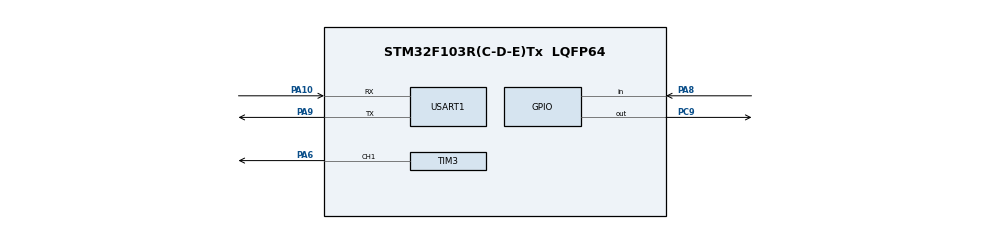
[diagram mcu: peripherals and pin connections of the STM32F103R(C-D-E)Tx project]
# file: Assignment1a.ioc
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Dma.Request0=USART1_RX
Dma.Request1=USART1_TX
Dma.USART1_RX.0.Direction=DMA_PERIPH_TO_MEMORY
Dma.USART1_RX.0.Instance=DMA1_Channel5
Dma.USART1_RX.0.MemDataAlignment=DMA_MDATAALIGN_BYTE
Dma.USART1_RX.0.MemInc=DMA_MINC_ENABLE
Dma.USART1_RX.0.Mode=DMA_NORMAL
Dma.USART1_RX.0.PeriphDataAlignment=DMA_PDATAALIGN_BYTE
Dma.USART1_RX.0.PeriphInc=DMA_PINC_DISABLE
Dma.USART1_RX.0.Priority=DMA_PRIORITY_LOW
Dma.USART1_TX.1.Direction=DMA_MEMORY_TO_PERIPH
Dma.USART1_TX.1.Instance=DMA1_Channel4
Dma.USART1_TX.1.MemDataAlignment=DMA_MDATAALIGN_BYTE
Dma.USART1_TX.1.MemInc=DMA_MINC_ENABLE
Dma.USART1_TX.1.Mode=DMA_NORMAL
Dma.USART1_TX.1.PeriphDataAlignment=DMA_PDATAALIGN_BYTE
Dma.USART1_TX.1.PeriphInc=DMA_PINC_DISABLE
Dma.USART1_TX.1.Priority=DMA_PRIORITY_LOW
Mcu.Family=STM32F1
Mcu.Name=STM32F103R(C-D-E)Tx
Mcu.Package=LQFP64
NVIC.DMA1_Channel4_IRQn=true\:0\:0\:false\:false\:true\:false\:true\:true
NVIC.DMA1_Channel5_IRQn=true\:0\:0\:false\:false\:true\:false\:true\:true
NVIC.PriorityGroup=NVIC_PRIORITYGROUP_4
PA10.Mode=Asynchronous
PA10.Signal=USART1_RX
PA13.Mode=Serial_Wire
PA13.Signal=SYS_JTMS-SWDIO
PA14.Mode=Serial_Wire
PA14.Signal=SYS_JTCK-SWCLK
PA6.Signal=S_TIM3_CH1
PA8.Signal=GPIO_Input
PA9.Mode=Asynchronous
PA9.Signal=USART1_TX
PC9.Signal=GPIO_Output
ProjectManager.HeapSize=0x200
ProjectManager.StackSize=0x400
ProjectManager.TargetToolchain=STM32CubeIDE
RCC.APB1Freq_Value=8000000
RCC.APB2Freq_Value=8000000
SH.S_TIM3_CH1.0=TIM3_CH1,PWM Generation1 CH1
TIM3.Channel-PWM\ Generation1\ CH1=TIM_CHANNEL_1
USART1.VirtualMode=VM_ASYNC
VP_TIM1_VS_ClockSourceINT.Mode=Internal
VP_TIM3_VS_ClockSourceINT.Mode=Internal
board=custom

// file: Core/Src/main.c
/* USER CODE BEGIN Header */
/**
  ******************************************************************************
  * @file           : main.c
  * @brief          : Main program body
  ******************************************************************************
  * @attention
  *
  * Copyright (c) 2024 STMicroelectronics.
  * All rights reserved.
  *
  * This software is licensed under terms that can be found in the LICENSE file
  * in the root directory of this software component.
  * If no LICENSE file comes with this software, it is provided AS-IS.
  *
  ******************************************************************************
  */
/* USER CODE END Header */
#include "main.h"

/* USER CODE BEGIN Includes */
#include <stdio.h>
#include <stdlib.h>
#include <string.h>
/* USER CODE END Includes */

TIM_HandleTypeDef htim1;
TIM_HandleTypeDef htim3;

UART_HandleTypeDef huart1;
DMA_HandleTypeDef hdma_usart1_rx;
DMA_HandleTypeDef hdma_usart1_tx;

/* USER CODE BEGIN PV */
#define TRIG_PIN GPIO_PIN_9
#define TRIG_PORT GPIOC
#define ECHO_PIN GPIO_PIN_8
#define ECHO_PORT GPIOA

uint32_t pMillis;
uint32_t Value1 = 0;
uint32_t Value2 = 0;
uint16_t Distance = 0; //cm
/* USER CODE END PV */

void SystemClock_Config(void);
static void MX_GPIO_Init(void);
static void MX_DMA_Init(void);
static void MX_TIM1_Init(void);
static void MX_USART1_UART_Init(void);
static void MX_TIM3_Init(void);

int main(void)
{
	/*User code begin 1*/
	int CH1_DC = 0;
	uint8_t count = 0;
	char MSG[35] = {'\0'};
	/*User code end 1*/

	/*Reset of all peripherals, INitializes the Flash interface and the Systick*/
	HAL_Init();

	/*Configures the sys clock*/
	SystemClock_Config();

	//Initialize all configured peripherals
	MX_GPIO_Init();
	MX_TIM3_Init();
	MX_USART1_UART_Init();
	MX_TIM1_Init();
	MX_DMA_Init();

	//USER CODE BEGIN 2
	HAL_TIM_Base_Start(&htim1);
	HAL_GPIO_WritePin(TRIG_PORT, TRIG_PIN, GPIO_PIN_RESET); //pull TRIG pin LOW
	//USER CODE END 2

	//USER CODE BEGIN WHILE, INFINITE WHILE LOOP
	while (1)
	{
		HAL_GPIO_WritePin(TRIG_PORT, TRIG_PIN, GPIO_PIN_SET); //pull TRIG pin HIGH
		__HAL_TIM_SET_COUNTER(&htim1, 0);
		while(__HAL_TIM_GET_COUNTER(&htim1) < 10); //wait 10us
		HAL_GPIO_WritePin(TRIG_PORT, TRIG_PIN, GPIO_PIN_RESET); //pull TRIG pin LOW

		pMillis = HAL_GetTick(); //used for timeout, avoid infinite loop
		//wait for echo pin to go HIGH
		while(!(HAL_GPIO_ReadPin(ECHO_PORT, ECHO_PIN)) && pMillis + 10 > HAL_GetTick());
		Value1 = __HAL_TIM_GET_COUNTER(&htim1);

		pMillis = HAL_GetTick(); //used for timeout, avoid infinite loop
		//wait for echo pin to go LOW
		while((HAL_GPIO_ReadPin(ECHO_PORT, ECHO_PIN)) && pMillis + 50 > HAL_GetTick());
		Value2 = __HAL_TIM_GET_COUNTER(&htim1);

		Distance = (Value2-Value1)*0.034/2;
		sprintf(MSG, "Distance = %d\r\n", Distance);
		HAL_UART_Transmit(&huart1, MSG, sizeof(MSG), 100);
		HAL_Delay(500);

	}
	//USER CODE END WHILE
}

void SystemClock_Config(void)
{
  RCC_OscInitTypeDef RCC_OscInitStruct = {0};
  RCC_ClkInitTypeDef RCC_ClkInitStruct = {0};

  /** Initializes the RCC Oscillators according to the specified parameters
  * in the RCC_OscInitTypeDef structure.
  */
  RCC_OscInitStruct.OscillatorType = RCC_OSCILLATORTYPE_HSI;
  RCC_OscInitStruct.HSIState = RCC_HSI_ON;
  RCC_OscInitStruct.HSICalibrationValue = RCC_HSICALIBRATION_DEFAULT;
  RCC_OscInitStruct.PLL.PLLState = RCC_PLL_NONE;
  if (HAL_RCC_OscConfig(&RCC_OscInitStruct) != HAL_OK)
  {
    Error_Handler();
  }

  /** Initializes the CPU, AHB and APB buses clocks
  */
  RCC_ClkInitStruct.ClockType = RCC_CLOCKTYPE_HCLK|RCC_CLOCKTYPE_SYSCLK
                              |RCC_CLOCKTYPE_PCLK1|RCC_CLOCKTYPE_PCLK2;
  RCC_ClkInitStruct.SYSCLKSource = RCC_SYSCLKSOURCE_HSI;
  RCC_ClkInitStruct.AHBCLKDivider = RCC_SYSCLK_DIV1;
  RCC_ClkInitStruct.APB1CLKDivider = RCC_HCLK_DIV1;
  RCC_ClkInitStruct.APB2CLKDivider = RCC_HCLK_DIV1;

  if (HAL_RCC_ClockConfig(&RCC_ClkInitStruct, FLASH_LATENCY_0) != HAL_OK)
  {
    Error_Handler();
  }
}

static void MX_TIM1_Init(void)
{

  TIM_ClockConfigTypeDef sClockSourceConfig = {0};
  TIM_MasterConfigTypeDef sMasterConfig = {0};

  htim1.Instance = TIM1;
  htim1.Init.Prescaler = 0;
  htim1.Init.CounterMode = TIM_COUNTERMODE_UP;
  htim1.Init.Period = 65535;
  htim1.Init.ClockDivision = TIM_CLOCKDIVISION_DIV1;
  htim1.Init.RepetitionCounter = 0;
  htim1.Init.AutoReloadPreload = TIM_AUTORELOAD_PRELOAD_DISABLE;
  if (HAL_TIM_Base_Init(&htim1) != HAL_OK)
  {
    Error_Handler();
  }
  sClockSourceConfig.ClockSource = TIM_CLOCKSOURCE_INTERNAL;
  if (HAL_TIM_ConfigClockSource(&htim1, &sClockSourceConfig) != HAL_OK)
  {
    Error_Handler();
  }
  sMasterConfig.MasterOutputTrigger = TIM_TRGO_RESET;
  sMasterConfig.MasterSlaveMode = TIM_MASTERSLAVEMODE_DISABLE;
  if (HAL_TIMEx_MasterConfigSynchronization(&htim1, &sMasterConfig) != HAL_OK)
  {
    Error_Handler();
  }

}

static void MX_TIM3_Init(void)
{

  TIM_ClockConfigTypeDef sClockSourceConfig = {0};
  TIM_MasterConfigTypeDef sMasterConfig = {0};
  TIM_OC_InitTypeDef sConfigOC = {0};

  htim3.Instance = TIM3;
  htim3.Init.Prescaler = 0;
  htim3.Init.CounterMode = TIM_COUNTERMODE_UP;
  htim3.Init.Period = 65535;
  htim3.Init.ClockDivision = TIM_CLOCKDIVISION_DIV1;
  htim3.Init.AutoReloadPreload = TIM_AUTORELOAD_PRELOAD_DISABLE;
  if (HAL_TIM_Base_Init(&htim3) != HAL_OK)
  {
    Error_Handler();
  }
  sClockSourceConfig.ClockSource = TIM_CLOCKSOURCE_INTERNAL;
  if (HAL_TIM_ConfigClockSource(&htim3, &sClockSourceConfig) != HAL_OK)
  {
    Error_Handler();
  }
  if (HAL_TIM_PWM_Init(&htim3) != HAL_OK)
  {
    Error_Handler();
  }
  sMasterConfig.MasterOutputTrigger = TIM_TRGO_RESET;
  sMasterConfig.MasterSlaveMode = TIM_MASTERSLAVEMODE_DISABLE;
  if (HAL_TIMEx_MasterConfigSynchronization(&htim3, &sMasterConfig) != HAL_OK)
  {
    Error_Handler();
  }
  sConfigOC.OCMode = TIM_OCMODE_PWM1;
  sConfigOC.Pulse = 0;
  sConfigOC.OCPolarity = TIM_OCPOLARITY_HIGH;
  sConfigOC.OCFastMode = TIM_OCFAST_DISABLE;
  if (HAL_TIM_PWM_ConfigChannel(&htim3, &sConfigOC, TIM_CHANNEL_1) != HAL_OK)
  {
    Error_Handler();
  }
  HAL_TIM_MspPostInit(&htim3);

}

static void MX_USART1_UART_Init(void)
{

  huart1.Instance = USART1;
  huart1.Init.BaudRate = 115200;
  huart1.Init.WordLength = UART_WORDLENGTH_8B;
  huart1.Init.StopBits = UART_STOPBITS_1;
  huart1.Init.Parity = UART_PARITY_NONE;
  huart1.Init.Mode = UART_MODE_TX_RX;
  huart1.Init.HwFlowCtl = UART_HWCONTROL_NONE;
  huart1.Init.OverSampling = UART_OVERSAMPLING_16;
  if (HAL_UART_Init(&huart1) != HAL_OK)
  {
    Error_Handler();
  }

}

static void MX_DMA_Init(void)
{

  /* DMA controller clock enable */
  __HAL_RCC_DMA1_CLK_ENABLE();

  /* DMA interrupt init */
  /* DMA1_Channel4_IRQn interrupt configuration */
  HAL_NVIC_SetPriority(DMA1_Channel4_IRQn, 0, 0);
  HAL_NVIC_EnableIRQ(DMA1_Channel4_IRQn);
  /* DMA1_Channel5_IRQn interrupt configuration */
  HAL_NVIC_SetPriority(DMA1_Channel5_IRQn, 0, 0);
  HAL_NVIC_EnableIRQ(DMA1_Channel5_IRQn);

}

static void MX_GPIO_Init(void)
{
  GPIO_InitTypeDef GPIO_InitStruct = {0};

  /* GPIO Ports Clock Enable */
  __HAL_RCC_GPIOA_CLK_ENABLE();
  __HAL_RCC_GPIOC_CLK_ENABLE();

  /*Configure GPIO pin Output Level */
  HAL_GPIO_WritePin(GPIOC, GPIO_PIN_9, GPIO_PIN_RESET);

  /*Configure GPIO pin : PC9 */
  GPIO_InitStruct.Pin = GPIO_PIN_9;
  GPIO_InitStruct.Mode = GPIO_MODE_OUTPUT_PP;
  GPIO_InitStruct.Pull = GPIO_NOPULL;
  GPIO_InitStruct.Speed = GPIO_SPEED_FREQ_LOW;
  HAL_GPIO_Init(GPIOC, &GPIO_InitStruct);

  /*Configure GPIO pin : PA8 */
  GPIO_InitStruct.Pin = GPIO_PIN_8;
  GPIO_InitStruct.Mode = GPIO_MODE_INPUT;
  GPIO_InitStruct.Pull = GPIO_NOPULL;
  HAL_GPIO_Init(GPIOA, &GPIO_InitStruct);

}

void Error_Handler(void)
{
  __disable_irq();
  while (1)
  {
  }
}
